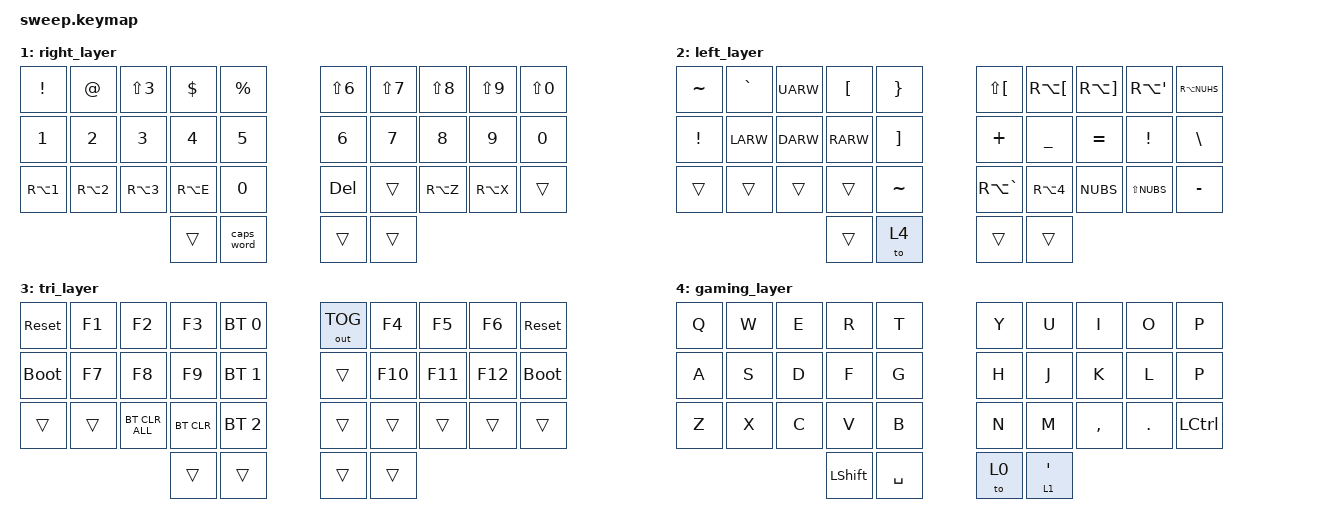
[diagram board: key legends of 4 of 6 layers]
// Copyright (c) 2022 The ZMK Contributors
// SPDX-License-Identifier: MIT

#include <behaviors.dtsi>
#include <dt-bindings/zmk/keys.h>
#include <dt-bindings/zmk/bt.h>
#include <dt-bindings/zmk/mouse.h>
#include <dt-bindings/zmk/outputs.h>
// #include <zmk-helpers/helper.h>
// #include "zmk-helpers/key-labels/34.h"

// Home row mods macro
#define HRML(k1,k2,k3,k4) &ht LGUI k1  &ht LALT k2  &ht LSHFT k3  &ht LCTRL k4
#define HRMR(k1,k2,k3,k4) &ht RCTRL k1  &ht RSHFT k2  &ht LALT k3  &ht RGUI k4

// ZMK_UNICODE_PAIR(n_tilde,   N0, N0, F, N1,   N0, N0, D, N1)

/ {
    behaviors {
        ht: hold_tap {
            compatible = "zmk,behavior-hold-tap";
            #binding-cells = <2>;
            flavor = "tap-preferred";
            tapping-term-ms = <200>;
            quick-tap-ms = <150>;
            require-prior-idle-ms = <100>;
            bindings = <&kp>, <&kp>;
        };
    };

    combos {
        compatible = "zmk,combos";
        combo_esc {
            timeout-ms = <50>;
            key-positions = <12 13>;
            bindings = <&kp ESC>;
        };
        combo_enter {
            timeout-ms = <50>;
            key-positions = <31 32>;
            bindings = <&kp RET>;
        };
        combo_bt0 {
            timeout-ms = <50>;
            key-positions = <00 24>;
            bindings = <&bt BT_SEL 0>;
        };
        combo_bt1 {
            timeout-ms = <50>;
            key-positions = <01 24>;
            bindings = <&bt BT_SEL 1>;
        };
        combo_bt2 {
            timeout-ms = <50>;
            key-positions = <02 24>;
            bindings = <&bt BT_SEL 2>;
        };
        combo_bt3 {
            timeout-ms = <50>;
            key-positions = <03 24>;
            bindings = <&bt BT_SEL 3>;
        };
        combo_bt4 {
            timeout-ms = <50>;
            key-positions = <04 24>;
            bindings = <&bt BT_SEL 4>;
        };
        combo_btclear {
            timeout-ms = <50>;
            key-positions = <22 24>;
            bindings = <&bt BT_CLR>;
        };
        combo_canaria {
            timeout-ms = <50>;
            key-positions = <10 14>;
            bindings = <&to 5>;
        };
        combo_home {
            timeout-ms = <50>;
            key-positions = <20 24>;
            bindings = <&to 0>;
        };
    };

    conditional_layers {
        compatible = "zmk,conditional-layers";
        tri_layer {
            if-layers = <1 2>;
            then-layer = <3>;
        };
    };

    keymap {
        compatible = "zmk,keymap";
        default_layer {
            bindings = <
        //╭──────────┬──────────┬──────────┬──────────┬──────────╮   ╭──────────┬──────────┬──────────┬──────────┬──────────╮
        //│  Q       │  W       │  E       │  R       │  T       │   │  Y       │  U       │  I       │  O       │  P       │
            &kp Q      &kp W      &kp E      &kp R      &kp T          &kp Y      &kp U      &kp I      &kp O      &kp P
        //├──────────┼──────────┼──────────┼──────────┼──────────┤   ├──────────┼──────────┼──────────┼──────────┼──────────┤
        //│  A       │  S       │  D       │  F       │  G       │   │  H       │  J       │  K       │  L       │ ' "      │
            HRML(A,        S,         D,         F)     &kp G          &kp H      HRMR(J,        K,         L,     SEMI)
        //├──────────┼──────────┼──────────┼──────────┼──────────┤   ├──────────┼──────────┼──────────┼──────────┼──────────┤
        //│  Z       │  X       │  C       │  V       │  B       │   │  N       │  M       │ ,        │ .        │ - _      │
            &kp Z      &kp X      &kp C      &kp V      &kp B          &kp N      &kp M      &kp COMMA  &kp DOT    &kp FSLH
        //╰──────────┴──────────┴──────────┼──────────┼──────────┤   ├──────────┼──────────┼──────────┴──────────┴──────────╯
                                            &lt 2 TAB   &kp SPACE     &kp BSPC  &lt 1 SQT
        //                                 ╰──────────┴──────────╯   ╰──────────┴──────────╯
            >;
        };

        right_layer {
            bindings = <
        //╭──────────┬──────────┬──────────┬──────────┬──────────╮   ╭──────────┬──────────┬──────────┬──────────┬──────────╮
        //│ !        │  "       │   ·      │  $       │ %        │   │ &        │ /        │ (        │     )    │  =       │
            &kp EXCL    &kp AT   &kp LS(N3)  &kp DLLR   &kp PRCNT     &kp LS(N6) &kp LS(N7) &kp LS(N8) &kp LS(N9) &kp LS(N0)
        //├──────────┼──────────┼──────────┼──────────┼──────────┤   ├──────────┼──────────┼──────────┼──────────┼──────────┤
        //│ 1        │  2       │  3       │  4       │ 5        │   │ 6        │ 7        │ 8        │ 9        │ 0        │
            &kp N1     &kp N2     &kp N3     &kp N4     &kp N5         &kp N6     &kp N7     &kp N8     &kp N9     &kp N0
        //├──────────┼──────────┼──────────┼──────────┼──────────┤   ├──────────┼──────────┼──────────┼──────────┼──────────┤
        //│ │        │  @       │  ·       │  4       │  0       │   │          │          │ «        │ »        │          │
           &kp RA(N1) &kp RA(N2) &kp RA(N3) &kp RA(E)   &kp N0         &kp DEL     &trans    &kp RA(Z)  &kp RA(X)  &trans
        //╰──────────┴──────────┴──────────┼──────────┼──────────┤   ├──────────┼──────────┼──────────┴──────────┴──────────╯
                                             &trans    &caps_word      &trans     &trans
        //                                 ╰──────────┴──────────╯   ╰──────────┴──────────╯
            >;
        };

        left_layer {
            bindings = <
        //╭──────────┬──────────┬──────────┬──────────┬──────────╮   ╭──────────┬──────────┬──────────┬──────────┬──────────╮
        //│ ª        │  º       │  UP      │  `       │ *        │   │  ^       │  (       │  )       │  {       │  }       │
           &kp TILDE   &kp GRAVE  &kp UARW   &kp LBKT   &kp RBRC     &kp LS(LBKT) &kp RA(LBKT) &kp RA(RBKT) &kp RA(SQT) &kp RA(NUHS)
        //├──────────┼──────────┼──────────┼──────────┼──────────┤   ├──────────┼──────────┼──────────┼──────────┼──────────┤
        //│  !       │  LEFT    │  DOWN    │  RIGHT   │ +        │   │  ¿       │  ?       │  ¡       │  !       │  ç       │
            &kp EXCL   &kp LARW    &kp DARW  &kp RARW  &kp RBKT       &kp PLUS   &kp UNDER  &kp EQUAL  &kp EXCL    &kp BSLH
        //├──────────┼──────────┼──────────┼──────────┼──────────┤   ├──────────┼──────────┼──────────┼──────────┼──────────┤
        //│          │          │          │          │          │   │  &       │  ~       │  <       │  >       │ '        │
            &trans     &trans     &trans     &trans    &kp TILDE     &kp RA(GRAVE) &kp RA(N4) &kp NUBS &kp LS(NUBS) &kp MINUS
        //╰──────────┴──────────┴──────────┼──────────┼──────────┤   ├──────────┼──────────┼──────────┴──────────┴──────────╯
                                             &trans     &to 4          &trans     &trans
        //                                 ╰──────────┴──────────╯   ╰──────────┴──────────╯
            >;
        };

        tri_layer {
            bindings = <
        //╭──────────┬──────────┬──────────┬──────────┬──────────╮   ╭──────────┬──────────┬──────────┬──────────┬──────────╮
        //│ RESET    │          │          │          │PROFILE 0 │   │          │          │          │          │  RESET   │
           &sys_reset  &kp F1     &kp F2     &kp F3    &bt BT_SEL 0  &out OUT_TOG &kp F4     &kp F5     &kp F6    &sys_reset
        //├──────────┼──────────┼──────────┼──────────┼──────────┤   ├──────────┼──────────┼──────────┼──────────┼──────────┤
        //│BOOTLOADER│          │          │          │PROFILE 1 │   │          │          │          │          │BOOTLOADER│
          &bootloader  &kp F7     &kp F8     &kp F9    &bt BT_SEL 1    &trans     &kp F10    &kp F11    &kp F12   &bootloader
        //├──────────┼──────────┼──────────┼──────────┼──────────┤   ├──────────┼──────────┼──────────┼──────────┼──────────┤
        //│          │          │          │ CLEAR BT │PROFILE 2 │   │          │          │          │          │          │
            &trans     &trans    &bt BT_CLR_ALL &bt BT_CLR &bt BT_SEL 2  &trans     &trans     &trans     &trans     &trans
        //╰──────────┴──────────┴──────────┼──────────┼──────────┤   ├──────────┼──────────┼──────────┴──────────┴──────────╯
                                             &trans     &trans         &trans     &trans
        //                                 ╰──────────┴──────────╯   ╰──────────┴──────────╯
            >;
        };

        gaming_layer {
            bindings = <
        //╭──────────┬──────────┬──────────┬──────────┬──────────╮   ╭──────────┬──────────┬──────────┬──────────┬──────────╮
        //│  Q       │  W       │  E       │  R       │  T       │   │  Y       │  U       │  I       │  O       │  P       │
            &kp Q      &kp W      &kp E      &kp R      &kp T          &kp Y      &kp U      &kp I      &kp O      &kp P
        //├──────────┼──────────┼──────────┼──────────┼──────────┤   ├──────────┼──────────┼──────────┼──────────┼──────────┤
        //│  A       │  S       │  D       │  F       │  G       │   │  H       │  J       │  K       │  L       │ ' "      │
            &kp A      &kp S      &kp D      &kp F      &kp G          &kp H      &kp J      &kp K      &kp L      &kp P
        //├──────────┼──────────┼──────────┼──────────┼──────────┤   ├──────────┼──────────┼──────────┼──────────┼──────────┤
        //│  Z       │  X       │  C       │  V       │  B       │   │  N       │  M       │ , <      │ . >      │ / ?      │
            &kp Z      &kp X      &kp C      &kp V      &kp B          &kp N      &kp M      &kp COMMA  &kp DOT    &kp LCTRL
        //╰──────────┴──────────┴──────────┼──────────┼──────────┤   ├──────────┼──────────┼──────────┴──────────┴──────────╯
                                            &kp LSHIFT  &kp SPACE     &to 0       &lt 1 SQT
        //                                 ╰──────────┴──────────╯   ╰──────────┴──────────╯
            >;
        };

        canaria_layer { // https://github.com/christoofar/canaria
            bindings = <
        //╭──────────┬──────────┬──────────┬──────────┬──────────╮   ╭──────────┬──────────┬──────────┬──────────┬──────────╮
        //│  W       │  L       │  Y       │  P       │  B       │   │  F       │  J       │  O       │  U       │  :       │
            &kp W      &kp L      &kp Y      &kp P      &kp B          &kp F      &kp J      &kp O      &kp U      &kp LS(DOT)
        //├──────────┼──────────┼──────────┼──────────┼──────────┤   ├──────────┼──────────┼──────────┼──────────┼──────────┤
        //│  C       │  R       │  S       │  T       │  G       │   │  M       │  N       │  E       │  I       │  A       │
            HRML(C,        R,         S,         T)     &kp G          &kp M      HRMR(N,        E,         I,     A)
        //├──────────┼──────────┼──────────┼──────────┼──────────┤   ├──────────┼──────────┼──────────┼──────────┼──────────┤
        //│  Q       │  Z       │  V       │  D       │  K       │   │  X       │  H       │ /        │ ,        │  .       │
            &kp Q      &kp Z      &kp V      &kp D      &kp K          &kp X      &kp H     &kp LS(N7)  &kp COMMA   &kp DOT
        //╰──────────┴──────────┴──────────┼──────────┼──────────┤   ├──────────┼──────────┼──────────┴──────────┴──────────╯
                                            &lt 2 TAB   &kp SPACE     &kp BSPC  &lt 1 SQT
        //                                 ╰──────────┴──────────╯   ╰──────────┴──────────╯
            >;
        };

    };
};
